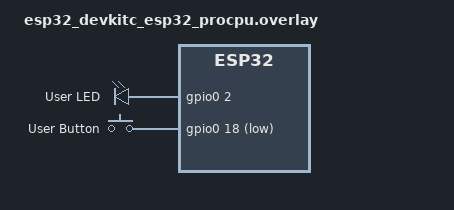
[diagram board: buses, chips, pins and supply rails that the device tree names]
/ {
    leds {
        compatible = "gpio-leds";

        led0: led_0 {
            gpios = <&gpio0 2 GPIO_ACTIVE_HIGH>;
            label = "User LED";
        };
    };

    buttons {
        compatible = "gpio-keys";

        button0: button_0 {
            gpios = <&gpio0 18 (GPIO_PULL_UP | GPIO_ACTIVE_LOW)>;
            label = "User Button";
        };
    };

    aliases {
        led0 = &led0;
        sw0 = &button0;
    };
};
